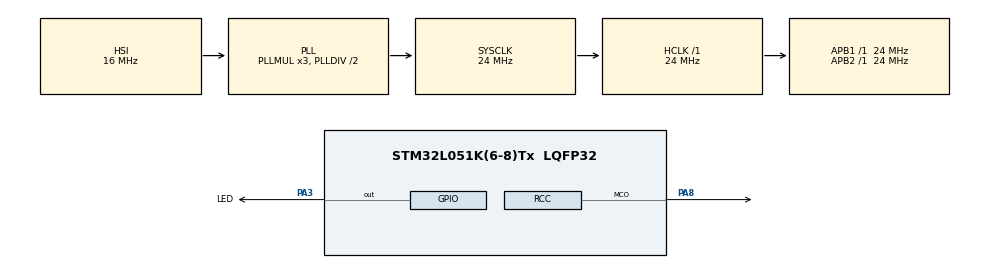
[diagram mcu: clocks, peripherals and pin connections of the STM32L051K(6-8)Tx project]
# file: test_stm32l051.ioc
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Mcu.Family=STM32L0
Mcu.Name=STM32L051K(6-8)Tx
Mcu.Package=LQFP32
PA3.GPIO_Label=LED
PA3.Signal=GPIO_Output
PA8.Mode=Clock-out
PA8.Signal=RCC_MCO
PC14-OSC32_IN.Mode=LSE-External-Oscillator
PC14-OSC32_IN.Signal=RCC_OSC32_IN
PC15-OSC32_OUT.Mode=LSE-External-Oscillator
PC15-OSC32_OUT.Signal=RCC_OSC32_OUT
ProjectManager.HeapSize=0x200
ProjectManager.StackSize=0x400
ProjectManager.TargetToolchain=Makefile
RCC.AHBFreq_Value=24000000
RCC.APB1Freq_Value=24000000
RCC.APB1TimFreq_Value=24000000
RCC.APB2Freq_Value=24000000
RCC.APB2TimFreq_Value=24000000
RCC.HCLKFreq_Value=24000000
RCC.HSI16_VALUE=16000000
RCC.HSI_VALUE=16000000
RCC.MSI_VALUE=2097000
RCC.RCC_MCOSource=RCC_MCO1SOURCE_LSE
RCC.SYSCLKFreq_VALUE=24000000
RCC.SYSCLKSource=RCC_SYSCLKSOURCE_PLLCLK
RCC.VCOOutputFreq_Value=48000000
board=custom

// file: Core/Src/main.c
/**
  ******************************************************************************
  * @file           : main.c
  * @brief          : Main program body
  ******************************************************************************
  ** This notice applies to any and all portions of this file
  * that are not between comment pairs USER CODE BEGIN and
  * USER CODE END. Other portions of this file, whether
  * inserted by the user or by software development tools
  * are owned by their respective copyright owners.
  *
  * COPYRIGHT(c) 2018 STMicroelectronics
  *
  * Redistribution and use in source and binary forms, with or without modification,
  * are permitted provided that the following conditions are met:
  *   1. Redistributions of source code must retain the above copyright notice,
  *      this list of conditions and the following disclaimer.
  *   2. Redistributions in binary form must reproduce the above copyright notice,
  *      this list of conditions and the following disclaimer in the documentation
  *      and/or other materials provided with the distribution.
  *   3. Neither the name of STMicroelectronics nor the names of its contributors
  *      may be used to endorse or promote products derived from this software
  *      without specific prior written permission.
  *
  * THIS SOFTWARE IS PROVIDED BY THE COPYRIGHT HOLDERS AND CONTRIBUTORS "AS IS"
  * AND ANY EXPRESS OR IMPLIED WARRANTIES, INCLUDING, BUT NOT LIMITED TO, THE
  * IMPLIED WARRANTIES OF MERCHANTABILITY AND FITNESS FOR A PARTICULAR PURPOSE ARE
  * DISCLAIMED. IN NO EVENT SHALL THE COPYRIGHT HOLDER OR CONTRIBUTORS BE LIABLE
  * FOR ANY DIRECT, INDIRECT, INCIDENTAL, SPECIAL, EXEMPLARY, OR CONSEQUENTIAL
  * DAMAGES (INCLUDING, BUT NOT LIMITED TO, PROCUREMENT OF SUBSTITUTE GOODS OR
  * SERVICES; LOSS OF USE, DATA, OR PROFITS; OR BUSINESS INTERRUPTION) HOWEVER
  * CAUSED AND ON ANY THEORY OF LIABILITY, WHETHER IN CONTRACT, STRICT LIABILITY,
  * OR TORT (INCLUDING NEGLIGENCE OR OTHERWISE) ARISING IN ANY WAY OUT OF THE USE
  * OF THIS SOFTWARE, EVEN IF ADVISED OF THE POSSIBILITY OF SUCH DAMAGE.
  *
  ******************************************************************************
  */
#include "main.h"
#include "stm32l0xx_hal.h"

/* USER CODE BEGIN Includes */
#include "hw.h"
#include "low_power_manager.h"
#include "lora.h"
#include "bsp.h"
#include "timeServer.h"
#include "vcom.h"
#include "version.h"
/* USER CODE END Includes */

/*!
 * CAYENNE_LPP is myDevices Application server.
 */
//#define CAYENNE_LPP
#define LPP_DATATYPE_DIGITAL_INPUT 0x0
#define LPP_DATATYPE_DIGITAL_OUTPUT 0x1
#define LPP_DATATYPE_HUMIDITY 0x68
#define LPP_DATATYPE_TEMPERATURE 0x67
#define LPP_DATATYPE_BAROMETER 0x73
#define LPP_APP_PORT 99
/*!
 * Defines the application data transmission duty cycle. 5s, value in [ms].
 */
#define APP_TX_DUTYCYCLE 10000
/*!
 * LoRaWAN Adaptive Data Rate
 * @note Please note that when ADR is enabled the end-device should be static
 */
#define LORAWAN_ADR_STATE LORAWAN_ADR_ON
/*!
 * LoRaWAN Default data Rate Data Rate
 * @note Please note that LORAWAN_DEFAULT_DATA_RATE is used only when ADR is disabled
 */
#define LORAWAN_DEFAULT_DATA_RATE DR_0
/*!
 * LoRaWAN application port
 * @note do not use 224. It is reserved for certification
 */
#define LORAWAN_APP_PORT 2
/*!
 * LoRaWAN default endNode class port
 */
#define LORAWAN_DEFAULT_CLASS CLASS_A
/*!
 * LoRaWAN default confirm state
 */
#define LORAWAN_DEFAULT_CONFIRM_MSG_STATE LORAWAN_UNCONFIRMED_MSG
/*!
 * User application data buffer size
 */
#define LORAWAN_APP_DATA_BUFF_SIZE 64

/* USER CODE BEGIN PV */
/* Private variables ---------------------------------------------------------*/
/*!
 * User application data
 */
static uint8_t AppDataBuff[LORAWAN_APP_DATA_BUFF_SIZE];

/*!
 * User application data structure
 */
//static lora_AppData_t AppData={ AppDataBuff,  0 ,0 };
lora_AppData_t AppData = {AppDataBuff, 0, 0};

/* Private macro -------------------------------------------------------------*/
/* Private function prototypes -----------------------------------------------*/

/* call back when LoRa endNode has received a frame*/
static void LORA_RxData(lora_AppData_t *AppData);

/* call back when LoRa endNode has just joined*/
static void LORA_HasJoined(void);

/* call back when LoRa endNode has just switch the class*/
static void LORA_ConfirmClass(DeviceClass_t Class);

/* call back when server needs endNode to send a frame*/
static void LORA_TxNeeded(void);

/* LoRa endNode send request*/
static void Send(void);

/* start the tx process*/
static void LoraStartTx(TxEventType_t EventType);

/* tx timer callback function*/
static void OnTxTimerEvent(void);

/* Private variables ---------------------------------------------------------*/
/* load Main call backs structure*/
static LoRaMainCallback_t LoRaMainCallbacks = {HW_GetBatteryLevel,
                                               HW_GetTemperatureLevel,
                                               HW_GetUniqueId,
                                               HW_GetRandomSeed,
                                               LORA_RxData,
                                               LORA_HasJoined,
                                               LORA_ConfirmClass,
                                               LORA_TxNeeded};

/*!
 * Specifies the state of the application LED
 */
static uint8_t AppLedStateOn = RESET;

static TimerEvent_t TxTimer;

#ifdef USE_B_L072Z_LRWAN1
/*!
 * Timer to handle the application Tx Led to toggle
 */
static TimerEvent_t TxLedTimer;
static void OnTimerLedEvent(void);
#endif
/* !
 *Initialises the Lora Parameters
 */
static LoRaParam_t LoRaParamInit = {LORAWAN_ADR_STATE,
                                    LORAWAN_DEFAULT_DATA_RATE,
                                    LORAWAN_PUBLIC_NETWORK};

/* USER CODE END PV */

void SystemClock_Config(void);
static void MX_GPIO_Init(void);

/* USER CODE BEGIN PFP */
/* Private function prototypes -----------------------------------------------*/

/* USER CODE END PFP */

int main(void)
{

  /* MCU Configuration----------------------------------------------------------*/

  /* Reset of all peripherals, Initializes the Flash interface and the Systick. */
  HAL_Init();

  /* Configure the system clock */
  SystemClock_Config();

  /* USER CODE BEGIN SysInit */
  //MX_GPIO_Init();
  Radio.IoInit();
  HW_SPI_Init();
  /* USER CODE END SysInit */

  /* USER CODE BEGIN 2 */
  /*Disbale Stand-by mode*/
  LPM_SetOffMode(LPM_APPLI_Id, LPM_Disable);

  PRINTF("VERSION: %X\n\r", VERSION);

  /* Configure the Lora Stack*/
  LORA_Init(&LoRaMainCallbacks, &LoRaParamInit);

  LORA_Join();

  LoraStartTx(TX_ON_TIMER);
  /* USER CODE END 2 */

  /* Infinite loop */
  /* USER CODE BEGIN WHILE */
  while (1)
  {

    LoRaMacProcess();
    DISABLE_IRQ();
    /* if an interrupt has occurred after DISABLE_IRQ, it is kept pending
     * and cortex will not enter low power anyway  */

#ifndef LOW_POWER_DISABLE
    LPM_EnterLowPower();
#endif

    ENABLE_IRQ();
    /* USER CODE END WHILE */
    /* USER CODE BEGIN 3 */
    //HAL_GPIO_TogglePin(LED_GPIO_Port, LED_Pin);
    /* Insert delay 100 ms */
    //HAL_Delay(500);
  }
  /* USER CODE END 3 */
}

void SystemClock_Config(void)
{

  RCC_OscInitTypeDef RCC_OscInitStruct;
  RCC_ClkInitTypeDef RCC_ClkInitStruct;

  /**Configure the main internal regulator output voltage
    */
  __HAL_PWR_VOLTAGESCALING_CONFIG(PWR_REGULATOR_VOLTAGE_SCALE1);

  /**Configure LSE Drive Capability
    */
  HAL_PWR_EnableBkUpAccess();

  __HAL_RCC_LSEDRIVE_CONFIG(RCC_LSEDRIVE_LOW);

  /**Initializes the CPU, AHB and APB busses clocks
    */
  RCC_OscInitStruct.OscillatorType = RCC_OSCILLATORTYPE_HSI | RCC_OSCILLATORTYPE_LSE;
  RCC_OscInitStruct.LSEState = RCC_LSE_ON;
  RCC_OscInitStruct.HSIState = RCC_HSI_ON;
  RCC_OscInitStruct.HSICalibrationValue = 16;
  RCC_OscInitStruct.PLL.PLLState = RCC_PLL_ON;
  RCC_OscInitStruct.PLL.PLLSource = RCC_PLLSOURCE_HSI;
  RCC_OscInitStruct.PLL.PLLMUL = RCC_PLLMUL_3;
  RCC_OscInitStruct.PLL.PLLDIV = RCC_PLLDIV_2;
  if (HAL_RCC_OscConfig(&RCC_OscInitStruct) != HAL_OK)
  {
    _Error_Handler(__FILE__, __LINE__);
  }

  /**Initializes the CPU, AHB and APB busses clocks
    */
  RCC_ClkInitStruct.ClockType = RCC_CLOCKTYPE_HCLK | RCC_CLOCKTYPE_SYSCLK | RCC_CLOCKTYPE_PCLK1 | RCC_CLOCKTYPE_PCLK2;
  RCC_ClkInitStruct.SYSCLKSource = RCC_SYSCLKSOURCE_PLLCLK;
  RCC_ClkInitStruct.AHBCLKDivider = RCC_SYSCLK_DIV1;
  RCC_ClkInitStruct.APB1CLKDivider = RCC_HCLK_DIV1;
  RCC_ClkInitStruct.APB2CLKDivider = RCC_HCLK_DIV1;

  if (HAL_RCC_ClockConfig(&RCC_ClkInitStruct, FLASH_LATENCY_1) != HAL_OK)
  {
    _Error_Handler(__FILE__, __LINE__);
  }

  HAL_RCC_MCOConfig(RCC_MCO1, RCC_MCO1SOURCE_LSE, RCC_MCODIV_1);

  /**Configure the Systick interrupt time
    */
  HAL_SYSTICK_Config(HAL_RCC_GetHCLKFreq() / 1000);

  /**Configure the Systick
    */
  HAL_SYSTICK_CLKSourceConfig(SYSTICK_CLKSOURCE_HCLK);

  /* SysTick_IRQn interrupt configuration */
  HAL_NVIC_SetPriority(SysTick_IRQn, 0, 0);
}

/** Configure pins as
        * Analog
        * Input
        * Output
        * EVENT_OUT
        * EXTI
     PA8   ------> RCC_MCO
*/
static void MX_GPIO_Init(void)
{

  GPIO_InitTypeDef GPIO_InitStruct;

  /* GPIO Ports Clock Enable */
  __HAL_RCC_GPIOC_CLK_ENABLE();
  __HAL_RCC_GPIOA_CLK_ENABLE();

  /*Configure GPIO pin Output Level */
  HAL_GPIO_WritePin(LED_GPIO_Port, LED_Pin, GPIO_PIN_RESET);

  /*Configure GPIO pin : LED_Pin */
  GPIO_InitStruct.Pin = LED_Pin;
  GPIO_InitStruct.Mode = GPIO_MODE_OUTPUT_PP;
  GPIO_InitStruct.Pull = GPIO_NOPULL;
  GPIO_InitStruct.Speed = GPIO_SPEED_FREQ_LOW;
  HAL_GPIO_Init(LED_GPIO_Port, &GPIO_InitStruct);

  /*Configure GPIO pin : PA8 */
  GPIO_InitStruct.Pin = GPIO_PIN_8;
  GPIO_InitStruct.Mode = GPIO_MODE_AF_PP;
  GPIO_InitStruct.Pull = GPIO_NOPULL;
  GPIO_InitStruct.Speed = GPIO_SPEED_FREQ_LOW;
  GPIO_InitStruct.Alternate = GPIO_AF0_MCO;
  HAL_GPIO_Init(GPIOA, &GPIO_InitStruct);
}

void _Error_Handler(char *file, int line)
{
  while (1)
  {
  }
}

/************************ (C) COPYRIGHT STMicroelectronics *****END OF FILE****/
